# GD32H7xx register map
File version: 1.0
CPU: CM7 r1p2, little endian, MPU, FPU, 4 interrupt priority bits
Registers are 32-bit, read-write, reset 0x0 unless marked. A register's access mark holds for its fields unless they carry their own. Offsets are from the block's base; [hi:lo] are bit positions; {n}, {i} and the like mark numbered series; 'fields as' and 'values as' point back to an identical list.

## TRIGSEL — Trigger selection controller
Base 0x40018400
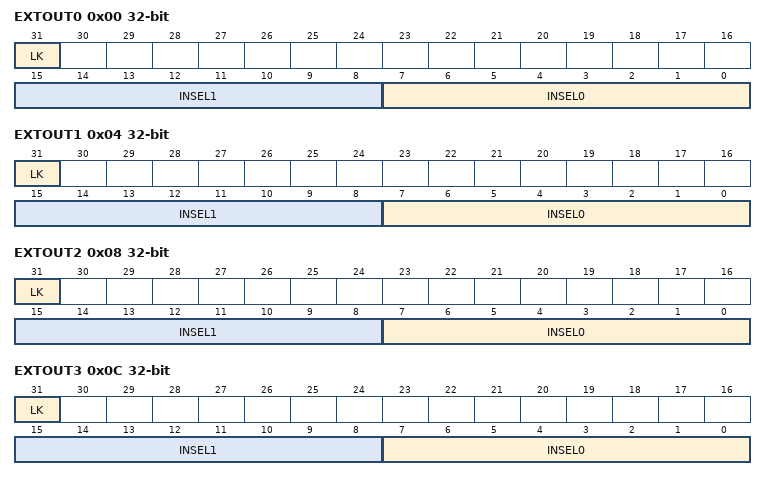
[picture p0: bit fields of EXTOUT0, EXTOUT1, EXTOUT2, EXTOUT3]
0x00 EXTOUT0 access per field — Trigger selection for EXTOUT0 register
  [31] LK ro — TRIGSEL register lock
  [15:8] INSEL1 rw — Trigger input source selection for output1
  [7:0] INSEL0 rw — Trigger input source selection for output0
0x04 EXTOUT1 access per field — Trigger selection for EXTOUT1 register
  [31] LK 未知模式 — TRIGSEL register lock
  [15:8] INSEL1 rw — Trigger input source selection for output1
  [7:0] INSEL0 rw — Trigger input source selection for output0
0x08 EXTOUT2 access per field — Trigger selection for EXTOUT2 register
  fields as EXTOUT0
0x0C EXTOUT3 access per field — Trigger selection for EXTOUT3 register
  fields as EXTOUT1
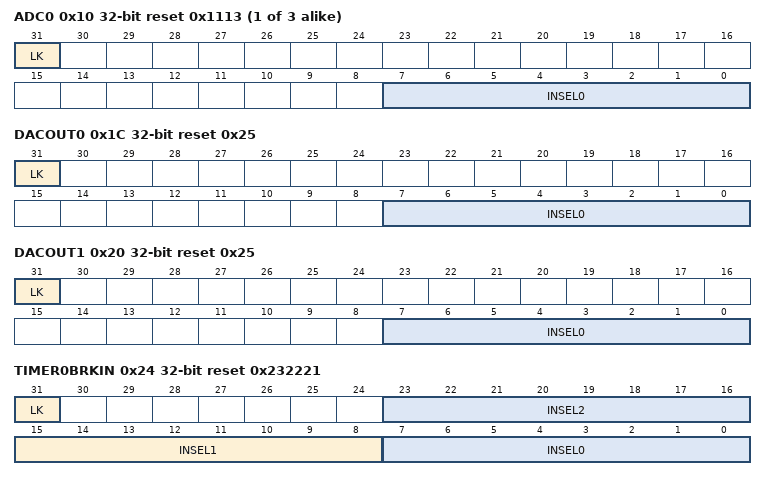
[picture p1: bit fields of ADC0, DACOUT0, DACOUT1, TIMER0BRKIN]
{0x10+4i} ADC{i} access per field reset 0x1113 (i=0..2) — Trigger selection for ADC{i} register
  [31] LK ro — TRIGSEL register lock
  [7:0] INSEL0 rw — Trigger input source selection for output0
0x1C DACOUT0 access per field reset 0x25 — Trigger selection for DAC_OUT0 register
  fields as ADC0
0x20 DACOUT1 access per field reset 0x25 — Trigger selection for DAC_OUT1 register
  fields as ADC0
0x24 TIMER0BRKIN access per field reset 0x232221 — Trigger selection for TIMER0_BRKIN register
  [31] LK ro — TRIGSEL register lock
  [23:16] INSEL2 rw — Trigger input source selection for output2
  [15:8] INSEL1 rw — Trigger input source selection for output1
  [7:0] INSEL0 rw — Trigger input source selection for output0
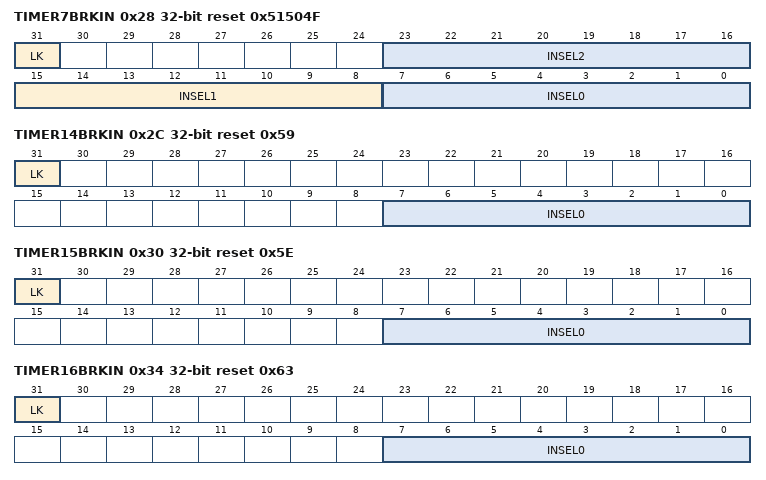
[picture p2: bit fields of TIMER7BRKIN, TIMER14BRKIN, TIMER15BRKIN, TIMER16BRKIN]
0x28 TIMER7BRKIN access per field reset 0x51504F — Trigger selection for TIMER7_BRKIN register
  fields as TIMER0BRKIN
0x2C TIMER14BRKIN access per field reset 0x59 — Trigger selection for TIMER14_BRKIN register
  fields as ADC0
0x30 TIMER15BRKIN access per field reset 0x5E — Trigger selection for TIMER15_BRKIN register
  fields as ADC0
0x34 TIMER16BRKIN access per field reset 0x63 — Trigger selection for TIMER16_BRKIN register
  fields as ADC0
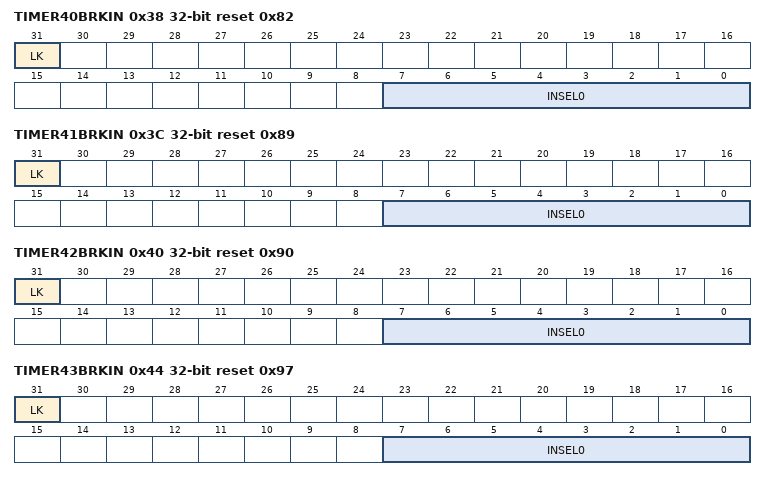
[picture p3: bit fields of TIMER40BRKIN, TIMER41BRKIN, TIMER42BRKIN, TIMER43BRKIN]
0x38 TIMER40BRKIN access per field reset 0x82 — Trigger selection for TIMER40_BRKIN register
  fields as ADC0
0x3C TIMER41BRKIN access per field reset 0x89 — Trigger selection for TIMER41_BRKIN register
  fields as ADC0
0x40 TIMER42BRKIN access per field reset 0x90 — Trigger selection for TIMER42_BRKIN register
  fields as ADC0
0x44 TIMER43BRKIN access per field reset 0x97 — Trigger selection for TIMER43_BRKIN register
  fields as ADC0
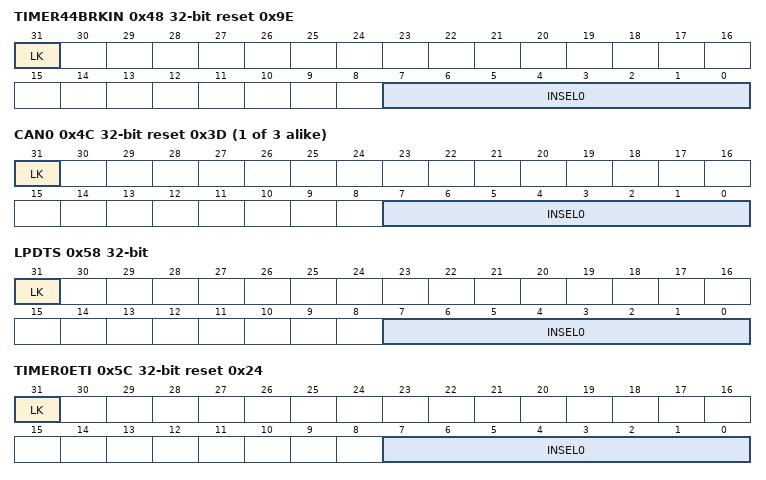
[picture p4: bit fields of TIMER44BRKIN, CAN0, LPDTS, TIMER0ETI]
0x48 TIMER44BRKIN access per field reset 0x9E — Trigger selection for TIMER44_BRKIN register
  fields as ADC0
{0x4C+4i} CAN{i} access per field reset 0x3D (i=0..2) — Trigger selection for CAN{i} register
  fields as ADC0
0x58 LPDTS access per field — Trigger selection for LPDTS register
  fields as ADC0
0x5C TIMER0ETI access per field reset 0x24 — Trigger selection for TIMER0_ETI register
  fields as ADC0
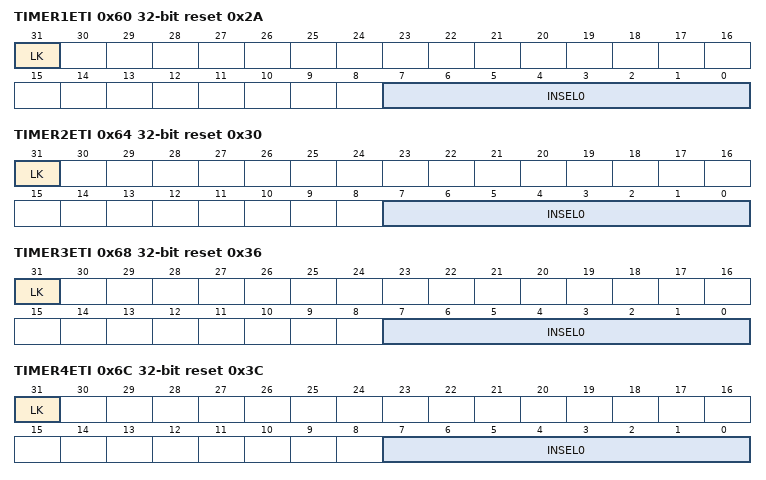
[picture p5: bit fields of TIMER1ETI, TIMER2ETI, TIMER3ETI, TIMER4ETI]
0x60 TIMER1ETI access per field reset 0x2A — Trigger selection for TIMER1_ETI register
  fields as ADC0
0x64 TIMER2ETI access per field reset 0x30 — Trigger selection for TIMER2_ETI register
  fields as ADC0
0x68 TIMER3ETI access per field reset 0x36 — Trigger selection for TIMER3_ETI register
  fields as ADC0
0x6C TIMER4ETI access per field reset 0x3C — Trigger selection for TIMER4_ETI register
  fields as ADC0
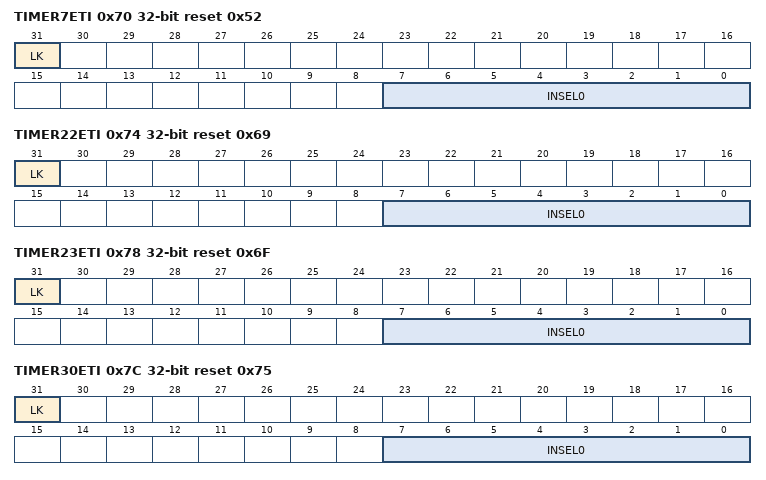
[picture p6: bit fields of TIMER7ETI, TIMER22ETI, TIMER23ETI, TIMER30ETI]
0x70 TIMER7ETI access per field reset 0x52 — Trigger selection for TIMER7_ETI register
  fields as ADC0
0x74 TIMER22ETI access per field reset 0x69 — Trigger selection for TIMER22_ETI register
  fields as ADC0
0x78 TIMER23ETI access per field reset 0x6F — Trigger selection for TIMER23_ETI register
  fields as ADC0
0x7C TIMER30ETI access per field reset 0x75 — Trigger selection for TIMER30_ETI register
  fields as ADC0
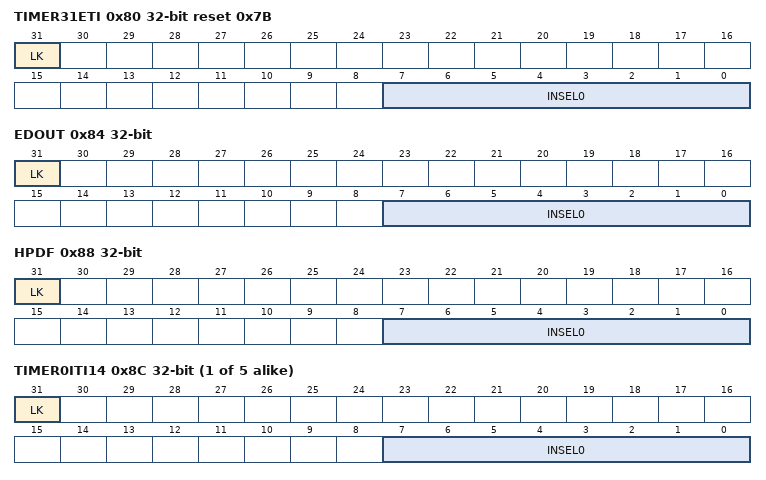
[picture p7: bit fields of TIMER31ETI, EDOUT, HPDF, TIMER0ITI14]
0x80 TIMER31ETI access per field reset 0x7B — Trigger selection for TIMER31_ETI register
  fields as ADC0
0x84 EDOUT access per field — Trigger selection for EDOUT register
  fields as ADC0
0x88 HPDF access per field — Trigger selection for HPDF_ITRG register
  fields as ADC0
{0x8C+4i} TIMER{i}ITI14 access per field (i=0..4) — Trigger selection for TIMER{i}_ITI14 register
  fields as ADC0
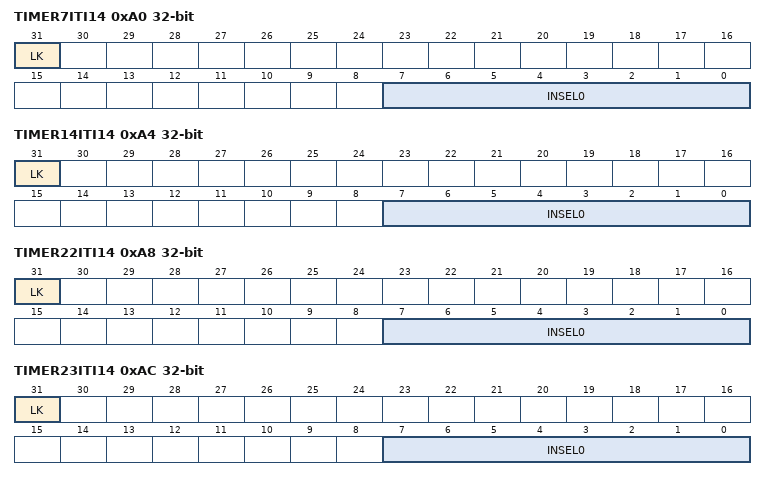
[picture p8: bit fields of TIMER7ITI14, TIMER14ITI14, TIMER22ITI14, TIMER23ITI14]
0xA0 TIMER7ITI14 access per field — Trigger selection for TIMER7_ITI14 register
  fields as ADC0
0xA4 TIMER14ITI14 access per field — Trigger selection for TIMER14_ITI14 register
  fields as ADC0
0xA8 TIMER22ITI14 access per field — Trigger selection for TIMER22_ITI14 register
  fields as ADC0
0xAC TIMER23ITI14 access per field — Trigger selection for TIMER23_ITI14 register
  fields as ADC0
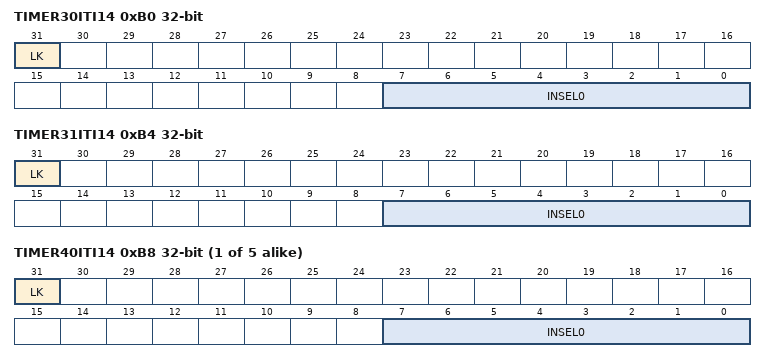
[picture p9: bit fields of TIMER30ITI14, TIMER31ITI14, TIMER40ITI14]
0xB0 TIMER30ITI14 access per field — Trigger selection for TIMER30_ITI14 register
  fields as ADC0
0xB4 TIMER31ITI14 access per field — Trigger selection for TIMER31_ITI14 register
  fields as ADC0
{0x18+4i} TIMER{i}ITI14 access per field (i=40..44) — Trigger selection for TIMER{i}_ITI14 register
  fields as ADC0
